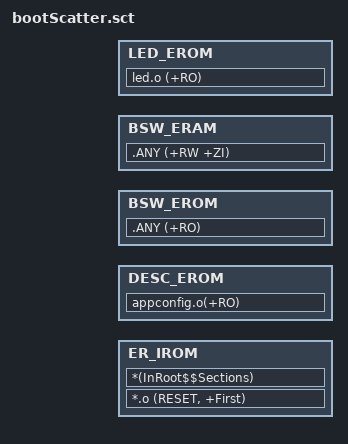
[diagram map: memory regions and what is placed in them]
#! armcc -E
#include "./scatterConfig.h"

; *************************************************************
; *** Scatter-Loading Description File generated by uVision ***
; *************************************************************


; *************************************************************
; *** Application INIT module *********************************
; *************************************************************
INIT_ROM        INIT_RO_Base    INIT_RO_Size  {     ; load region size_region
    ER_IROM     INIT_RO_Base    INIT_RO_Size  {     ; load address = execution address
        *.o (RESET, +First)
        *(InRoot$$Sections)
    }
}

; *************************************************************
; *** Application DESC module *********************************
; *************************************************************
DESC_LROM       DESC_RO_Base    DESC_RO_Size  {     ; load region size_region
    DESC_EROM   DESC_RO_Base    DESC_RO_Size  {     ; load address = execution address
        appconfig.o(+RO)
    }
}

; *************************************************************
; *** Application BSW module *********************************
; *************************************************************
BSW_LROM        BSW_RO_Base     BSW_RO_Size  {      ; load region size_region
    BSW_EROM    BSW_RO_Base     BSW_RO_Size  {      ; load address = execution address
        .ANY (+RO)
    }
    BSW_ERAM    BSW_RW_Base     BSW_RW_Size {
        .ANY (+RW +ZI)
    }
}

; *************************************************************
; *** Application LED module *********************************
; *************************************************************
LED_LROM        LED_RO_Base     LED_RO_Size  {      ; load region size_region
    LED_EROM    LED_RO_Base     LED_RO_Size  {      ; load address = execution address
        led.o (+RO)
    }
}




